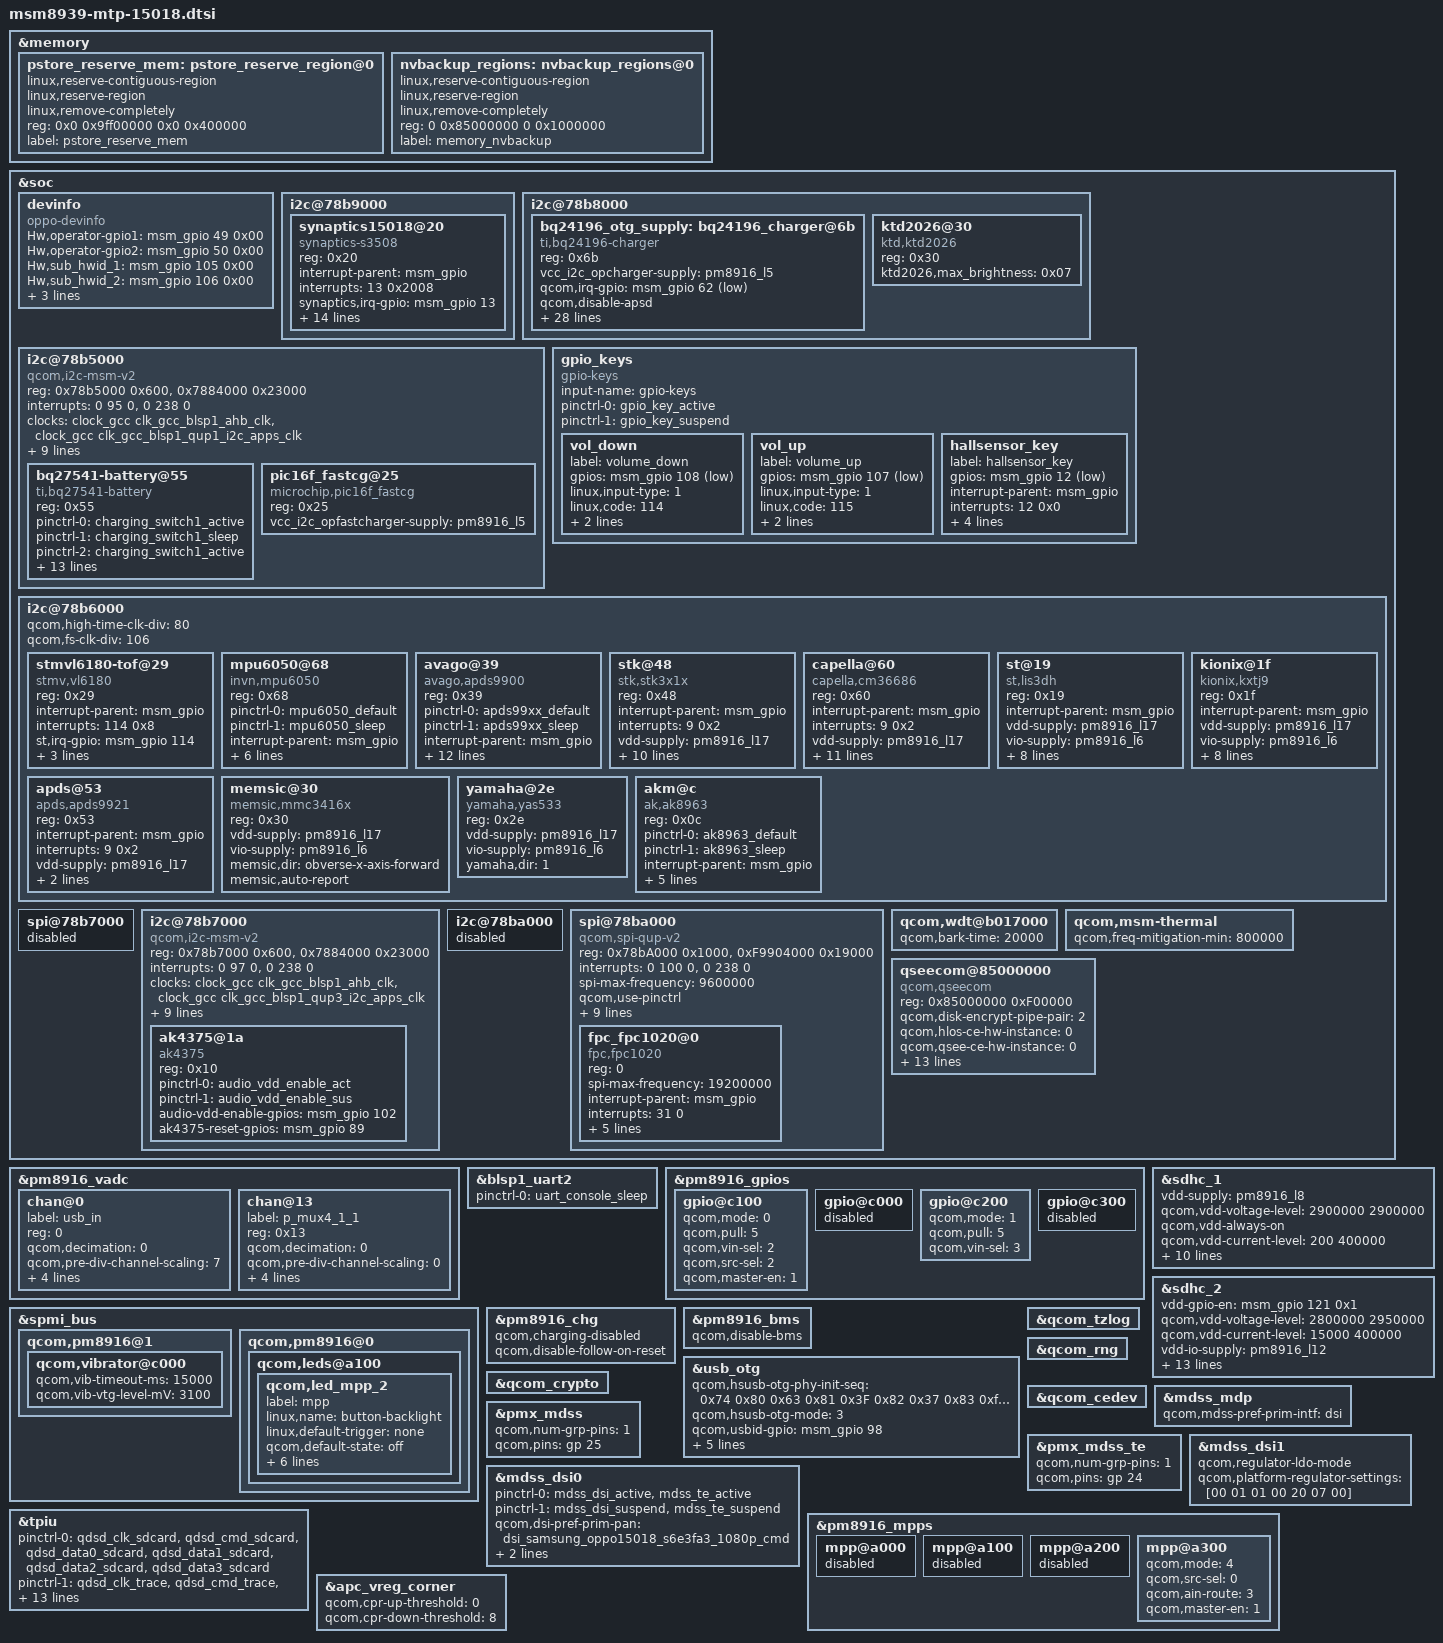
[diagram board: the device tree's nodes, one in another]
/* Copyright (c) 2014-2015, The Linux Foundation. All rights reserved.
 *
 * This program is free software; you can redistribute it and/or modify
 * it under the terms of the GNU General Public License version 2 and
 * only version 2 as published by the Free Software Foundation.
 *
 * This program is distributed in the hope that it will be useful,
 * but WITHOUT ANY WARRANTY; without even the implied warranty of
 * MERCHANTABILITY or FITNESS FOR A PARTICULAR PURPOSE.  See the
 * GNU General Public License for more details.
 */

#include "msm8939-audio-internal_codec-15018.dtsi"
#include "msm8939-camera-sensor-mtp-15018.dtsi"
#include "msm8939-mdss-15018.dtsi"
#include "msm8939-pinctrl-15018.dtsi"
#include "msm8939-regulator-15018.dtsi"
#include "msm-pm8916-15018.dtsi"

&memory {
	pstore_reserve_mem: pstore_reserve_region@0 {
		linux,reserve-contiguous-region;
		linux,reserve-region;
		linux,remove-completely;
		reg = <0x0 0x9ff00000 0x0 0x400000>;
		label = "pstore_reserve_mem";
	};

	nvbackup_regions: nvbackup_regions@0 {
		linux,reserve-contiguous-region;
		linux,reserve-region;
		linux,remove-completely;
		reg = <0 0x85000000 0 0x1000000>;
		label = "memory_nvbackup";
	};
};

&soc {
	devinfo {
		compatible = "oppo-devinfo";
		Hw,operator-gpio1 = <&msm_gpio 49 0x00>;
		Hw,operator-gpio2 = <&msm_gpio 50 0x00>;
		Hw,sub_hwid_1 = <&msm_gpio 105 0x00>;
		Hw,sub_hwid_2= <&msm_gpio 106 0x00>;
		pinctrl-names = "default";
		pinctrl-0 = <&hw_operator_gpio1_active
				&hw_operator_gpio2_active
				&hw_sub_gpio1_active
				&hw_sub_gpio2_active>;
	};

	i2c@78b9000 { /* BLSP1 QUP5 */
		synaptics15018@20 {
			compatible = "synaptics-s3508";
			reg = <0x20>;
			interrupt-parent = <&msm_gpio>;
			interrupts = <13 0x2008>;
			synaptics,irq-gpio = <&msm_gpio 13 0x2008>;
			pinctrl-names = "default";
			pinctrl-0 = <&ts_int_active>;
			synaptics,max-num-support = <10>;
			synaptics,max-x-point = <10>;
			synaptics,button-map= <200 200 2021>;
			synaptics,tx-rx-num = <18 32>;
			synaptics,display-coords = <1080 1920>;
			synaptics,panel-coords = <1080 1920>;
			synaptics,enable2v8-gpio = <&pm8916_gpios 2 0x00>;
			vcc_i2c_1v8-supply = <&pm8916_l5>;
			synaptics,black-gesture-enabled;
			synaptics,charger-pump-support;
			synaptics,i2c-pull-up;
			synaptics,power-down;
			synaptics,disable-gpios;
		};
	};

	i2c@78b8000 { /* BLSP1 QUP4 */
		bq24196_otg_supply: bq24196_charger@6b {
			status = "okay";
			compatible = "ti,bq24196-charger";
			reg = <0x6b>;

			vcc_i2c_opcharger-supply = <&pm8916_l5>;
			qcom,irq-gpio = <&msm_gpio 62 0x01>;

			qcom,disable-apsd;
			qcom,bms-psy-name = "bms";

			qcom,charger-inhibit-disabled;
			qcom,chg-vadc = <&pm8916_vadc>;
			qcom,chg-adc_tm = <&pm8916_adc_tm>;

			/* Charge termination current */
			qcom,iterm-ma = <150>;
			/* The minimum voltage drop for recharge */
			qcom,recharge-mv = <100>;
			qcom,fast-charger-project-sign= <1>;
			qcom,fastchg-current-max-ma = <2000>;
			qcom,input-current-max-ma = <2000>;
			qcom,float-voltage-mv = <4320>;

			qcom,hot_bat_decidegc = <530>;
			qcom,temp_hot_vfloat_mv = <4100>;
			qcom,temp_hot_fastchg_current_ma = <900>;

			qcom,warm_bat_decidegc = <450>;
			qcom,temp_warm_vfloat_mv = <4320>;
			qcom,temp_warm_fastchg_current_ma = <2000>;

			qcom,pre_normal_bat_decidegc = <160>;
			qcom,temp_pre_normal_vfloat_mv = <4320>;
			qcom,temp_pre_normal_fastchg_current_ma = <1500>;

			qcom,pre_cool_bat_decidegc = <120>;
			qcom,temp_pre_cool_vfloat_mv = <4200>;
			qcom,temp_pre_cool_fastchg_current_ma = <900>;

			qcom,cool_bat_decidegc = <0>;
			qcom,temp_cool_vfloat_mv = <4000>;
			qcom,temp_cool_fastchg_current_ma = <300>;

			qcom,cold_bat_decidegc = <30>;
			qcom,bat_present_decidegc = <200>;

			regulator-name = "bq24196_otg_vreg";
		};

		ktd2026@30 {
			status = "okay";
			compatible = "ktd,ktd2026";
			reg = <0x30>;

			/*
			 * 0x00: 0.125ma
			 * 0x07: 1ma
			 * 0x29: 5.25ma
			 * 0x4f: 10ma
			 * 0xbf-0xff: 24ma
			 */
			ktd2026,max_brightness = <0x07>;
		};
	};

	i2c@78b5000 { /* BLSP1 QUP1 */
		compatible = "qcom,i2c-msm-v2";
		#address-cells = <1>;
		#size-cells = <0>;
		reg-names = "qup_phys_addr", "bam_phys_addr";
		reg = <0x78b5000 0x600>,
		      <0x7884000 0x23000>;
		interrupt-names = "qup_irq", "bam_irq";
		interrupts = <0 95 0>, <0 238 0>;
		clocks = <&clock_gcc clk_gcc_blsp1_ahb_clk>,
			 <&clock_gcc clk_gcc_blsp1_qup1_i2c_apps_clk>;
		clock-names = "iface_clk", "core_clk";
		qcom,clk-freq-out = <100000>;
		qcom,clk-freq-in  = <19200000>;
		pinctrl-names = "i2c_active", "i2c_sleep";
		pinctrl-0 = <&i2c_1_active>;
		pinctrl-1 = <&i2c_1_sleep>;
		qcom,noise-rjct-scl = <0>;
		qcom,noise-rjct-sda = <0>;
		qcom,bam-pipe-idx-cons = <4>;
		qcom,bam-pipe-idx-prod = <5>;
		qcom,master-id = <86>;

		bq27541-battery@55 {
			status = "okay";
			compatible = "ti,bq27541-battery";
			reg = <0x55>;

			pinctrl-names = "switch1_act_switch2_act",
					"switch1_sleep_switch2_sleep", 
					"switch1_act_switch3_act",
					"switch1_sleep_switch3_sleep",
					"switch1_act_switch2_sleep",
					"switch1_sleep_switch2_act",
					"clock_active",
					"clock_sleep",
					"data_active",
					"data_sleep",
					"reset_active",
					"reset_sleep";
			pinctrl-0 = <&charging_switch1_active>;
			pinctrl-1 = <&charging_switch1_sleep>;
			pinctrl-2 = <&charging_switch1_active>;
			pinctrl-3 = <&charging_switch1_sleep>;
			pinctrl-4 = <&charging_switch1_active>;
			pinctrl-5 = <&charging_switch1_sleep>;
			pinctrl-6 = <&charging_clock_active>;
			pinctrl-7 = <&charging_clock_sleep>;
			pinctrl-8 = <&charging_data_active>;
			pinctrl-9 = <&charging_data_sleep>;
			pinctrl-10 = <&charging_reset_active>;
			pinctrl-11 = <&charging_reset_sleep>;

			qcom,charging_swtich1-gpio = <&msm_gpio 1 0x00>;
			qcom,charging_reset-gpio = <&msm_gpio 52 0x00>;
			qcom,charging_clock-gpio = <&msm_gpio 120 0x00>;
			qcom,charging_data-gpio = <&msm_gpio 109 0x00>;
		};

		pic16f_fastcg@25 {
			status = "okay";
			compatible = "microchip,pic16f_fastcg";
			reg = <0x25>;

			vcc_i2c_opfastcharger-supply = <&pm8916_l5>;
		};
	};

	gpio_keys {
		compatible = "gpio-keys";
		input-name = "gpio-keys";
		pinctrl-names = "tlmm_gpio_key_active", "tlmm_gpio_key_suspend";
		pinctrl-0 = <&gpio_key_active>;
		pinctrl-1 = <&gpio_key_suspend>;

		vol_down {
			label = "volume_down";
			gpios = <&msm_gpio 108 0x1>;
			linux,input-type = <1>;
			linux,code = <114>;
			gpio-key,wakeup;
			debounce-interval = <15>;
		};

		vol_up {
			label = "volume_up";
			gpios = <&msm_gpio 107 0x1>;
			linux,input-type = <1>;
			linux,code = <115>;
			gpio-key,wakeup;
			debounce-interval = <15>;
		};

		hallsensor_key {
			label = "hallsensor_key";
			gpios = <&msm_gpio 12 1>;
			interrupt-parent = <&msm_gpio>;
			interrupts = <12 0x0>;
			linux,input-type = <5>;
			linux,code = <0>;
			gpio-key,wakeup;
			debounce-interval = <150>;
		};
	};

	i2c@78b6000 { /* BLSP1 QUP2 */
		qcom,high-time-clk-div = <80>;
		qcom,fs-clk-div = <106>;

		stmvl6180-tof@29 { /* Proximity sensor */
			compatible = "stmv,vl6180";
			reg = <0x29>;
			interrupt-parent = <&msm_gpio>;
			interrupts = <114 0x8>;
			st,irq-gpio= <&msm_gpio 114 0x00>;
			st,standby-gpio = <&msm_gpio 51 0x00>;
			vdd_1v8-supply = <&pm8916_l17>;
			vcc_i2c_1v8-supply = <&pm8916_l6>;
		};

		mpu6050@68 { /* Gyroscope and accelerometer sensor combo */
			compatible = "invn,mpu6050";
			reg = <0x68>;
			pinctrl-names = "mpu_default","mpu_sleep";
			pinctrl-0 = <&mpu6050_default>;
			pinctrl-1 = <&mpu6050_sleep>;
			interrupt-parent = <&msm_gpio>;
			interrupts = <115 0x2>;
			vdd-supply = <&pm8916_l17>;
			vlogic-supply = <&pm8916_l16>;
			vi2c-supply = <&pm8916_l6>;
			invn,gpio-int = <&msm_gpio 115 0x2>;
			invn,place = "Portrait Down Back Side";
		};

		avago@39 { /* Ambient light and proximity sensor */
			compatible = "avago,apds9900";
			reg = <0x39>;
			pinctrl-names = "default","sleep";
			pinctrl-0 = <&apds99xx_default>;
			pinctrl-1 = <&apds99xx_sleep>;
			interrupt-parent = <&msm_gpio>;
			interrupts = <113 0x2002>;
			vdd-supply = <&pm8916_l17>;
			vio-supply = <&pm8916_l6>;
			avago,irq-gpio = <&msm_gpio 113 0x2002>;
			avago,ps-threshold = <600>;
			avago,ps-hysteresis-threshold = <500>;
			avago,ps-pulse = <10>;
			avago,ps-pgain = <0>;
			avago,als-B = <186>;
			avago,als-C = <75>;
			avago,als-D = <129>;
			avago,ga-value = <560>;
		};

		stk@48 {
			compatible = "stk,stk3x1x";
			reg = <0x48>;
			interrupt-parent = <&msm_gpio>;
			interrupts = <9 0x2>;
			vdd-supply = <&pm8916_l17>;
			vio-supply = <&pm8916_l6>;
			stk,irq-gpio = <&msm_gpio 9 0x02>;
			stk,transmittance = <340>;
			stk,state-reg = <0x00>;
			stk,psctrl-reg = <0x31>;
			stk,alsctrl-reg = <0x3a>;
			stk,ledctrl-reg = <0x3F>;
			stk,wait-reg = <0x10>;
			stk,ps-thdh = <1400>;
			stk,ps-thdl = <1300>;
		};

		capella@60 {
			compatible = "capella,cm36686";
			reg = <0x60>;
			interrupt-parent = <&msm_gpio>;
			interrupts = <9 0x2>;
			vdd-supply = <&pm8916_l17>;
			vio-supply = <&pm8916_l6>;
			capella,use-polling;
			capella,interrupt-gpio = <&msm_gpio 9 0x02>;
			capella,levels = <0x0A 0xA0 0xE1 0x140 0x280 0x500 0xA28 0x16A8 0x1F40 0x2800>;
			capella,ps_close_thd_set = <0xc8>; /* 200 */
			capella,ps_away_thd_set = <0xbe>; /* 190 */
			capella,als_gain = <500>;
			capella,ls_cmd = <0x44>; /* ALS_IT=160ms, INT_PERS=2*/
			capella,ps_conf1_val = <0x008d>; /* CM36686_PS_IT_1T | CM36686_PS_DR_1_40 | CM36686_PS_PERS_2 */
			capella,ps_conf3_val = <0x0202>; /* CM36686_PS_MS_NORMAL | CM36686_LED_I_100 | CM36686_PS_SMART_PERS_ENABLE */
		};

		st@19 { /* Accelerometer sensor */
			compatible = "st,lis3dh";
			reg = <0x19>;
			interrupt-parent = <&msm_gpio>;
			vdd-supply = <&pm8916_l17>;
			vio-supply = <&pm8916_l6>;
			st,min-interval = <5>;
			st,init-interval = <200>;
			st,axis-map-x = <1>;
			st,axis-map-y = <0>;
			st,axis-map-z = <2>;
			st,g-range = <2>;
			st,gpio-int1 = <&msm_gpio 112 0x2002>;
			st,negate-x;
		};

		kionix@1f { 
			compatible = "kionix,kxtj9";
			reg = <0x1f>;
			interrupt-parent = <&msm_gpio>;
			vdd-supply = <&pm8916_l17>;
			vio-supply = <&pm8916_l6>;
			kionix,min-interval = <5>;
			kionix,init-interval = <200>;
			kionix,axis-map-x = <1>;
			kionix,axis-map-y = <0>;
			kionix,axis-map-z = <2>;
			kionix,g-range = <2>;
			kionix,negate-x;
			kionix,res-12bit;
		};

		apds@53 {
			compatible = "apds,apds9921";
			reg = <0x53>;
			interrupt-parent = <&msm_gpio>;
			interrupts = <9 0x2>;
			vdd-supply = <&pm8916_l17>;
			vio-supply = <&pm8916_l6>;
			apds,irq-gpio = <&msm_gpio 9 0x02>;
		};

		memsic@30 { /* Magnetic field sensor */
			compatible = "memsic,mmc3416x";
			reg = <0x30>;
			vdd-supply = <&pm8916_l17>;
			vio-supply = <&pm8916_l6>;
			memsic,dir = "obverse-x-axis-forward";
			memsic,auto-report;
		};

		yamaha@2e { /* Magnetic field sensor */
			compatible = "yamaha,yas533";
			reg = <0x2e>;
			vdd-supply = <&pm8916_l17>;
			vio-supply = <&pm8916_l6>;
			yamaha,dir = <1>;
		};

		akm@c {
			compatible = "ak,ak8963";
			reg = <0x0c>;
			pinctrl-names = "ak8963_default", "ak8963_sleep";
			pinctrl-0 = <&ak8963_default>;
			pinctrl-1 = <&ak8963_sleep>;
			interrupt-parent = <&msm_gpio>;
			interrupts = <69 0x2>;
			vdd-supply = <&pm8916_l17>;
			vio-supply = <&pm8916_l6>;
			ak,layout = <0x6>;
			ak,auto-report;
		};
	};

	spi@78b7000 { /* BLSP1 QUP3 */
		status = "disabled";
	};

	i2c@78b7000 { /* BLSP1 QUP3 */
		compatible = "qcom,i2c-msm-v2";
		#address-cells = <1>;
		#size-cells = <0>;
		reg-names = "qup_phys_addr", "bam_phys_addr";
		reg = <0x78b7000 0x600>, <0x7884000 0x23000>;
		interrupt-names = "qup_irq", "bam_irq";
		interrupts = <0 97 0>, <0 238 0>;
		clocks = <&clock_gcc clk_gcc_blsp1_ahb_clk>,
			 <&clock_gcc clk_gcc_blsp1_qup3_i2c_apps_clk>;
		clock-names = "iface_clk", "core_clk";
		qcom,clk-freq-out = <400000>;
		qcom,clk-freq-in  = <19200000>;
		pinctrl-names = "i2c_active", "i2c_sleep";
		pinctrl-0 = <&i2c_3_active>;
		pinctrl-1 = <&i2c_3_sleep>;
		qcom,noise-rjct-scl = <0>;
		qcom,noise-rjct-sda = <0>;
		qcom,bam-pipe-idx-cons = <8>;
		qcom,bam-pipe-idx-prod = <9>;
		qcom,master-id = <86>;

		ak4375@1a {
			compatible = "ak4375";
			reg = <0x10>;
			pinctrl-names = "cdc_audio_enable_act",
					"cdc_audio_enable_sus";
			pinctrl-0 = <&audio_vdd_enable_act>;
			pinctrl-1 = <&audio_vdd_enable_sus>;
			audio-vdd-enable-gpios = <&msm_gpio 102 0x00>;
			ak4375-reset-gpios = <&msm_gpio 89 0x00>;
		};
	};

	i2c@78ba000 { /* BLSP1 QUP6 */
		status = "disabled";
	};

	spi@78ba000 {  /* BLSP1 QUP6 */
		compatible = "qcom,spi-qup-v2";
		#address-cells = <1>;
		#size-cells = <0>;
		reg-names = "spi_physical", "spi_bam_physical";
		reg = <0x78bA000 0x1000>, <0xF9904000 0x19000>;
		interrupt-names = "spi_irq", "spi_bam_irq";
		interrupts = <0 100 0>, <0 238 0>;
		spi-max-frequency = <9600000>;
		qcom,use-pinctrl;
		pinctrl-names = "default", "sleep";
		pinctrl-0 = <&spi6_default &spi6_cs0_active>;
		pinctrl-1 = <&spi6_sleep &spi6_cs0_sleep>;
		clocks = <&clock_gcc clk_gcc_blsp1_ahb_clk>,
				<&clock_gcc clk_gcc_blsp1_qup6_spi_apps_clk>;
		clock-names = "iface_clk", "core_clk";
		qcom,infinite-mode = <0>;
		qcom,ver-reg-exists;
		qcom,bam-consumer-pipe-index = <14>; //TODO
		qcom,bam-producer-pipe-index = <15>; //TODO
		qcom,master-id = <86>;
		status = "okay";

		fpc_fpc1020@0 {
			compatible = "fpc,fpc1020";
			reg = <0>;
			spi-max-frequency = <19200000>;
			interrupt-parent = <&msm_gpio>;
			interrupts = <31 0>;
			fpc,gpio_irq = <&msm_gpio 31 0x00>;
			fpc,gpio_reset = <&msm_gpio 95 0x00>;

			vdd_io-supply = <&pm8916_l5>; // 1.8V

			clocks = <&clock_gcc clk_gcc_blsp1_ahb_clk>,
				 <&clock_gcc clk_gcc_blsp1_qup6_spi_apps_clk>;
			clock-names = "iface_clk", "core_clk";
		};
	};

	qcom,wdt@b017000 {
		qcom,bark-time = <20000>;
	};

	qcom,msm-thermal {
		qcom,freq-mitigation-min = <800000>;
	};

	qseecom@85000000 {
		compatible = "qcom,qseecom";
		reg = <0x85000000 0xF00000>;
		reg-names = "secapp-region";
		qcom,disk-encrypt-pipe-pair = <2>;
		qcom,hlos-ce-hw-instance = <0>;
		qcom,qsee-ce-hw-instance = <0>;
		qcom,msm-bus,name = "qseecom-noc";
		qcom,msm-bus,num-cases = <4>;
		qcom,msm-bus,num-paths = <1>;
		qcom,support-bus-scaling;
		qcom,support-fde;
		qcom,msm-bus,vectors-KBps =
				<55 512 0 0>,
				<55 512 0 0>,
				<55 512 120000 1200000>,
				<55 512 393600 3936000>;
		clocks = <&clock_gcc clk_crypto_clk_src>,
				<&clock_gcc clk_gcc_crypto_clk>,
				<&clock_gcc clk_gcc_crypto_ahb_clk>,
				<&clock_gcc clk_gcc_crypto_axi_clk>;
		clock-names = "core_clk_src", "core_clk",
				"iface_clk", "bus_clk";
		qcom,ce-opp-freq = <100000000>;
	};
};

&pm8916_vadc {
	chan@0 {
		label = "usb_in";
		reg = <0>;
		qcom,decimation = <0>;
		qcom,pre-div-channel-scaling = <7>;
		qcom,calibration-type = "absolute";
		qcom,scale-function = <0>;
		qcom,hw-settle-time = <0>;
		qcom,fast-avg-setup = <0>;
	};

	chan@13 {
		label = "p_mux4_1_1";
		reg = <0x13>;
		qcom,decimation = <0>;
		qcom,pre-div-channel-scaling = <0>;
		qcom,calibration-type = "absolute";
		qcom,scale-function = <0>;
		qcom,hw-settle-time = <2>;
		qcom,fast-avg-setup = <0>;
	};
};

&blsp1_uart2 {
	status = "ok";
	pinctrl-names = "default";
	pinctrl-0 = <&uart_console_sleep>;
};

&pm8916_gpios {
	gpio@c100 { /* GPIO 2 */
		/* NFC_CLK_REQ */
		qcom,mode = <0>; /* QPNP_PIN_MODE_DIG_IN */
		qcom,pull = <5>; /* QPNP_PIN_PULL_NO */
		qcom,vin-sel = <2>; /* QPNP_PIN_VIN2 */
		qcom,src-sel = <2>; /* QPNP_PIN_SEL_FUNC_1 */
		qcom,master-en = <1>;
	};
};

&spmi_bus {
	qcom,pm8916@1 {
		qcom,vibrator@c000 {
			status = "okay";
			qcom,vib-timeout-ms = <15000>;
			qcom,vib-vtg-level-mV = <3100>;
		};
	};

	qcom,pm8916@0 {
		qcom,leds@a100 {
			status = "okay";
			qcom,led_mpp_2 {
				label = "mpp";
				linux,name = "button-backlight";
				linux,default-trigger = "none";
				qcom,default-state = "off";
				qcom,max-current = <40>;
				qcom,current-setting = <5>;
				qcom,id = <6>;
				qcom,mode = "manual";
				qcom,source-sel = <1>;
				qcom,mode-ctrl = <0x60>;
			};
		};
	};
};

&sdhc_1 {
	vdd-supply = <&pm8916_l8>;
	qcom,vdd-voltage-level = <2900000 2900000>;
	qcom,vdd-always-on;
	qcom,vdd-current-level = <200 400000>;

	vdd-io-supply = <&pm8916_l5>;
	qcom,vdd-io-always-on;
	qcom,vdd-io-lpm-sup;
	qcom,vdd-io-voltage-level = <1800000 1800000>;
	qcom,vdd-io-current-level = <200 60000>;

	pinctrl-names = "active", "sleep";
	pinctrl-0 = <&sdc1_clk_on &sdc1_cmd_on &sdc1_data_on>;
	pinctrl-1 = <&sdc1_clk_off &sdc1_cmd_off &sdc1_data_off>;

	qcom,nonremovable;

	status = "ok";
};

&sdhc_2 {
	vdd-gpio-en = <&msm_gpio 121 0x1>;
	qcom,vdd-voltage-level = <2800000 2950000>;
	qcom,vdd-current-level = <15000 400000>;

	vdd-io-supply = <&pm8916_l12>;
	qcom,vdd-io-voltage-level = <1800000 2950000>;
	qcom,vdd-io-current-level = <200 50000>;

	pinctrl-names = "default", "active", "sleep";
	pinctrl-0 = <&sdc2_cd_on &sim1_cd_on &sim2_cd_on>;
	pinctrl-1 = <&sdc2_clk_on &sdc2_cmd_on &sdc2_data_on &sdc2_cd_on>;
	pinctrl-2 = <&sdc2_clk_off &sdc2_cmd_off &sdc2_data_off &sdc2_cd_off>;

	#address-cells = <0>;
	interrupt-parent = <&sdhc_2>;
	interrupts = <0 1 2>;
	#interrupt-cells = <1>;
	interrupt-map-mask = <0xffffffff>;
	interrupt-map = <0 &intc 0 125 0
			1 &intc 0 221 0
			2 &msm_gpio 38 0>;
	interrupt-names = "hc_irq", "pwr_irq", "status_irq";
	cd-gpios = <&msm_gpio 38 0x0>;

	status = "ok";
};

&pm8916_chg {
	status = "ok";
	qcom,charging-disabled;
	qcom,disable-follow-on-reset;
};

&pm8916_bms {
	status = "ok";
	qcom,disable-bms;
};

&usb_otg {
	qcom,hsusb-otg-phy-init-seq =
		<0x74 0x80 0x63 0x81 0x3F 0x82 0x37 0x83 0xffffffff>;
	qcom,hsusb-otg-mode = <3>;
	qcom,usbid-gpio = <&msm_gpio 98 0>;
	pinctrl-names = "default", "active", "sleep";
	pinctrl-0 = <&usbid_default>;
	pinctrl-1 = <&usbid_default>;
	pinctrl-2 = <&usbid_sleep>;
	vbus_otg-supply = <&bq24196_otg_supply>;
	qcom,usbin-vadc = <&pm8916_vadc>;
};

&qcom_tzlog {
	status = "okay";
};

&qcom_rng {
	status = "okay";
};

&qcom_crypto {
	status = "okay";
};

&qcom_cedev {
	status = "okay";
};

&mdss_mdp {
	qcom,mdss-pref-prim-intf = "dsi";
};

&pmx_mdss {
	qcom,num-grp-pins = <1>;
	qcom,pins = <&gp 25>;
};

&pmx_mdss_te {
	qcom,num-grp-pins = <1>;
	qcom,pins = <&gp 24>;
};

#include "dsi-panel-oppo15018samsung_s6e3fa3_1080p_cmd.dtsi"

&mdss_dsi0 {
	pinctrl-names = "mdss_default", "mdss_sleep";
	pinctrl-0 = <&mdss_dsi_active &mdss_te_active>;
	pinctrl-1 = <&mdss_dsi_suspend &mdss_te_suspend>;

	qcom,dsi-pref-prim-pan = <&dsi_samsung_oppo15018_s6e3fa3_1080p_cmd>;

	qcom,platform-enable-gpio = <&pm8916_gpios 3 0>;
	qcom,platform-reset-gpio = <&msm_gpio 25 0>;
};

&mdss_dsi1 {
	qcom,regulator-ldo-mode;
	qcom,platform-regulator-settings = [00 01 01 00 20 07 00];
};

&pm8916_mpps {
	mpp@a000 { /* MPP 1 */
		/* VDD_PX */
		status = "disabled";
	};

	mpp@a100 { /* MPP 2 */
		/* HR LED */
		status = "disabled";
	};

	mpp@a200 { /* MPP 3 */
		/* VREF DAC */
		status = "disabled";
	};

	mpp@a300 { /* MPP 4 */
		/* ADC */
		qcom,mode = <4>; /* QPNP_PIN_MODE_AIN */
		qcom,src-sel = <0>; /* QPNP_PIN_SEL_FUNC_CONSTANT */
		qcom,ain-route = <3>; /* QPNP_PIN_AIN_AMUX_CH8 */
		qcom,master-en = <1>; /* Enable MPP */
	};
};

&pm8916_gpios {
	gpio@c000 { /* GPIO 1 */
		/* Battery UICC Alarm */
		status = "disabled";
	};

	gpio@c100 { /* GPIO 2 */
		/* NFC_CLK_REQ */
		qcom,mode = <0>; /* QPNP_PIN_MODE_DIG_IN */
		qcom,pull = <5>; /* QPNP_PIN_PULL_NO */
		qcom,vin-sel = <2>; /* QPNP_PIN_VIN2 */
		qcom,src-sel = <2>; /* QPNP_PIN_SEL_FUNC_1 */
		qcom,master-en = <1>;
	};

	gpio@c200 { /* GPIO 3 */
		/* External regulator control for WTR */
		status = "ok";
		qcom,mode = <1>; /* QPNP_PIN_MODE_DIG_OUT */
		qcom,pull = <5>; /* QPNP_PIN_PULL_NO */
		qcom,vin-sel = <3>; /* QPNP_PIN_VIN3 */
	};

	gpio@c300 { /* GPIO 4 */
		/* External regulator control for APC */
		status = "disabled";
	};
};

/* CoreSight */
&tpiu {
	pinctrl-names = "sdcard", "trace", "swduart",
			"swdtrc", "jtag", "spmi";
	/* NIDnT */
	pinctrl-0 = <&qdsd_clk_sdcard &qdsd_cmd_sdcard
		     &qdsd_data0_sdcard &qdsd_data1_sdcard
		     &qdsd_data2_sdcard &qdsd_data3_sdcard>;
	pinctrl-1 = <&qdsd_clk_trace &qdsd_cmd_trace
		     &qdsd_data0_trace &qdsd_data1_trace
		     &qdsd_data2_trace &qdsd_data3_trace>;
	pinctrl-2 = <&qdsd_cmd_swduart &qdsd_data0_swduart
		     &qdsd_data1_swduart &qdsd_data2_swduart
		     &qdsd_data3_swduart>;
	pinctrl-3 = <&qdsd_clk_swdtrc &qdsd_cmd_swdtrc
		     &qdsd_data0_swdtrc &qdsd_data1_swdtrc
		     &qdsd_data2_swdtrc &qdsd_data3_swdtrc>;
	pinctrl-4 = <&qdsd_cmd_jtag &qdsd_data0_jtag
		     &qdsd_data1_jtag &qdsd_data2_jtag
		     &qdsd_data3_jtag>;
	pinctrl-5 = <&qdsd_clk_spmi &qdsd_cmd_spmi
		     &qdsd_data0_spmi &qdsd_data3_spmi>;
};

&apc_vreg_corner {
		qcom,cpr-up-threshold = <0>;
		qcom,cpr-down-threshold = <8>;
};
